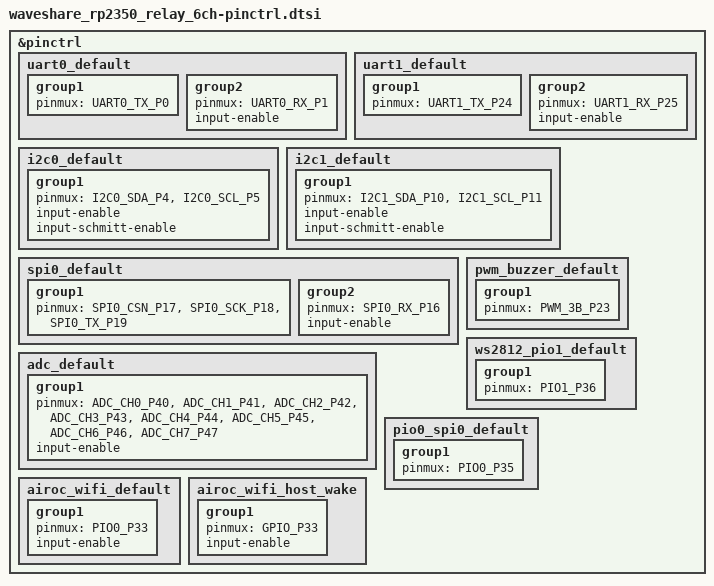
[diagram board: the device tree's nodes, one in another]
/*
 * SPDX-License-Identifier: Apache-2.0
 */

#include <zephyr/dt-bindings/pinctrl/rpi-pico-rp2350b-pinctrl.h>

&pinctrl {
	uart0_default: uart0_default {
		group1 {
			pinmux = <UART0_TX_P0>;
		};

		group2 {
			pinmux = <UART0_RX_P1>;
			input-enable;
		};
	};

	uart1_default: uart1_default {
		group1 {
			pinmux = <UART1_TX_P24>;
		};

		group2 {
			pinmux = <UART1_RX_P25>;
			input-enable;
		};
	};

	i2c0_default: i2c0_default {
		group1 {
			pinmux = <I2C0_SDA_P4>, <I2C0_SCL_P5>;
			input-enable;
			input-schmitt-enable;
		};
	};

	i2c1_default: i2c1_default {
		group1 {
			pinmux = <I2C1_SDA_P10>, <I2C1_SCL_P11>;
			input-enable;
			input-schmitt-enable;
		};
	};

	spi0_default: spi0_default {
		group1 {
			pinmux = <SPI0_CSN_P17>, <SPI0_SCK_P18>, <SPI0_TX_P19>;
		};

		group2 {
			pinmux = <SPI0_RX_P16>;
			input-enable;
		};
	};

	pwm_buzzer_default: pwm_buzzer_default {
		group1 {
			pinmux = <PWM_3B_P23>;
		};
	};

	ws2812_pio1_default: ws2812_pio1_default {
		group1 {
			pinmux = <PIO1_P36>;
		};
	};

	adc_default: adc_default {
		group1 {
			pinmux = <ADC_CH0_P40>, <ADC_CH1_P41>, <ADC_CH2_P42>, <ADC_CH3_P43>,
				 <ADC_CH4_P44>, <ADC_CH5_P45>, <ADC_CH6_P46>, <ADC_CH7_P47>;
			input-enable;
		};
	};

	pio0_spi0_default: pio0_spi0_default {
		/* GPIO34 is used for chip select, not assigned to the PIO */
		group1 {
			pinmux = <PIO0_P35>;
		};
	};

	airoc_wifi_default: airoc_wifi_default {
		/* Control of GPIO33 is done through the Wi-Fi driver */
		group1 {
			pinmux = <PIO0_P33>;
			input-enable;
		};
	};

	airoc_wifi_host_wake: airoc_wifi_host_wake {
		/* Assign GPIO33 to SIO (GPIO) for use as an interrupt source */
		group1 {
			pinmux = <GPIO_P33>;
			input-enable;
		};
	};
};
